# K1921VG5T register map
Vendor: NIIET; Series: K1921VKx; File version: 1.1
CPU: CM4 r0p1, Endian.LITTLE endian, MPU, FPU
Registers are 32-bit, read-write, reset 0x0 unless marked. A register's access mark holds for its fields unless they carry their own. Offsets are from the block's base; [hi:lo] are bit positions; lines under a group give offsets from that group; {n}, {i} and the like mark numbered series.

## FLASH — Flash status and control module
Base 0x50002000
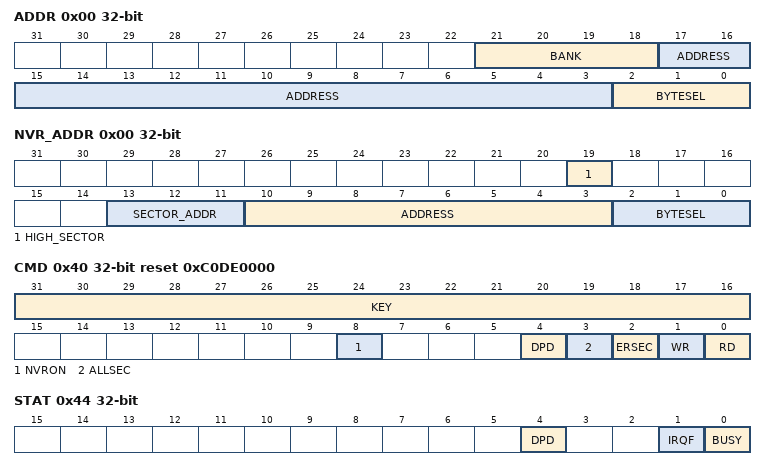
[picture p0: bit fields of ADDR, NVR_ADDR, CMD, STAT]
0x00 ADDR — Address Register
  [21:18] BANK — Address value for flash operations (Bank number)
  [17:3] ADDRESS — Address value to selected flash IP
  [2:0] BYTESEL — Address value for each byte
0x00 NVR_ADDR (alternate view of ADDR) — Address Register for NVR access
  [19] HIGH_SECTOR — Sector address value (msb) to selected flash IP
  [13:11] SECTOR_ADDR — Sector address value (lsb) to selected flash IP
  [10:3] ADDRESS — Address value within current sector to selected flash IP
  [2:0] BYTESEL — Address value for each byte
{0x10+4i} DATA[{i}] (i=0..3) group
  0x00 ? reset 0xFFFFFFFF — Data Register
    [31:0] VAL — Data register value for flash operations
0x40 CMD reset 0xC0DE0000 — Command Register
  [31:16] KEY wo — Magic Key for flash access "C0DE"
    0xC0DE=Access (magic Key for flash access)
  [8] NVRON — NVR access bit
  [4] DPD — Enter/Exit power down mode
  [3] ALLSEC — Select all sectors for erase
  [2] ERSEC — Erase sector enable command
  [1] WR — Write enable command
  [0] RD — Read enable command
0x44 STAT — Status Register
  [4] DPD ro — Flash IP in powerdown mode
  [1] IRQF — IRQ Flag set when command done. Set by hardware only if IRQEN bit is set.
  [0] BUSY ro — Busy status bit when command is processing
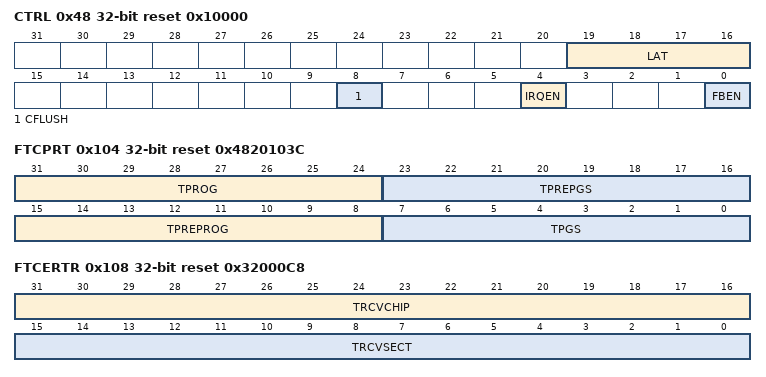
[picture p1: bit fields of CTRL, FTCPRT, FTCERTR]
0x48 CTRL reset 0x10000 — Control Register
  [19:16] LAT — Flash latency
  [8] CFLUSH wo — Flush internal buffer
  [4] IRQEN — Command Interrupt enable bit
  [0] FBEN — Fetch buffer Enable
0x100 FTCETR reset 0xEA60 — Flash Timing Control register (Erase time)
  [31:0] TSCE — Erase time value in cycles
0x104 FTCPRT reset 0x4820103C — Flash Timing Control register (Program time)
  [31:24] TPROG — Program time value in cycles
  [23:16] TPREPGS — PREPG to PROG2 time value in cycles
  [15:8] TPREPROG — Pre-program time value in cycles
  [7:0] TPGS — Web to PROG2 high time value in cycles
0x108 FTCERTR reset 0x32000C8 — Flash Timing Control register (Erase Recovery time)
  [31:16] TRCVCHIP — Chip erase recovery time value in cycles
  [15:0] TRCVSECT — Sector erase recovery time value in cycles
0x10C FTCPRTR reset 0x14 — Flash Timing Control register (Program Recovery time)
  [7:0] TRCVPROG — Program recovery time value in cycles

## RTC — RTC control registers
Base 0x50005000
0x00 TIME
  [31:0] VAL
0x04 ALARM1 reset 0xFFFFFFFF
  [31:0] VAL
0x08 ALARM2 reset 0xFFFFFFFF
  [31:0] VAL
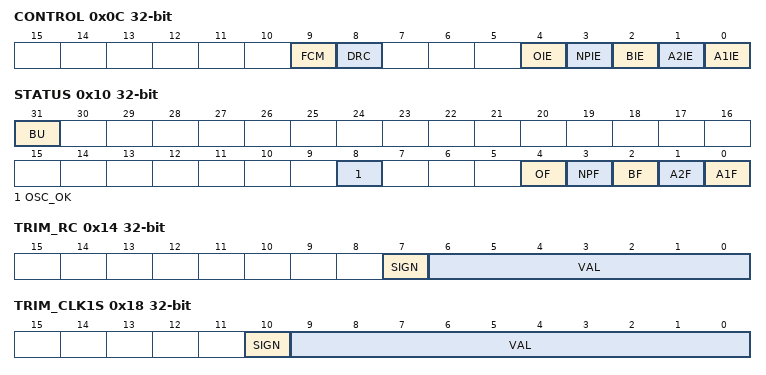
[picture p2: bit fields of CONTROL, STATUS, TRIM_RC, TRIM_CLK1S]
0x0C CONTROL
  [9] FCM — Use 32 kHz clock to time register increment
    0=NORMAL_MODE (The time register is incremented each second); 1=FAST_MODE (32 kHz clock is used to increment the time register)
  [8] DRC — Disable RC oscillator
  [4] OIE — Timer overflow interrupt enable
  [3] NPIE — Switch to normal power supply interrupt enable
  [2] BIE — Switch to battery supply interrupt enable
  [1] A2IE — ALARM2 = TIME interrupt enable
  [0] A1IE — ALARM1 = TIME interrupt enable
0x10 STATUS
  [31] BU ro — Battery supply is used status
  [8] OSC_OK ro — RC oscillator state is ok
  [4] OF — Timer overflow was detected
  [3] NPF — Switch to normal power supply was detected
  [2] BF — Switch to battery supply was detected
  [1] A2F — ALARM2 = TIME front was detected
  [0] A1F — ALARM1 = TIME front was detected
0x14 TRIM_RC — RC oscillator trim register
  [7] SIGN, [6:0] VAL
0x18 TRIM_CLK1S — Clock 1s trim register
  [10] SIGN, [9:0] VAL
{0x20+4i} GPR[{i}] (i=0..15) group
  0x00 ? — General purpose register
    [31:0] VAL

## WDT — Watchdog timer
Base 0x50006000
0x00 LOAD reset 0xFFFFFFFF — Watchdog Load Register
  [31:0] VAL — Begin value counter
0x04 VALUE ro reset 0xFFFFFFFF — Watchdog Value Register
  [31:0] VAL — Current value counter
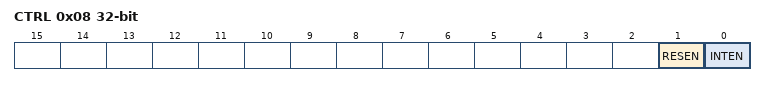
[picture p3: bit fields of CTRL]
0x08 CTRL — Watchdog Control Register
  [1] RESEN — Enable watchdog reset output
  [0] INTEN — Enable the interrupt event
0x0C INTCLR wo — Watchdog Clear Interrupt Register
  [31:0] WDTCLR — Reset interrupt WDT
0x10 RIS ro — Watchdog Raw Interrupt Status Register
  [0] RAWWDTINT — Raw interrupt status from the counter
0x14 MIS ro — Watchdog Interrupt Status Register
  [0] WDTINT — Enabled interrupt status from the counter
0xC00 LOCK wo — Watchdog Lock Register
  [0] REGWRDIS — Disable write to all registers Watchdog
